# HC32F448 register map
File version: 1.0
CPU: CM4 r0p1, little endian, MPU, FPU, 4 interrupt priority bits
Registers are 32-bit, read-write, reset 0x0 unless marked. A register's access mark holds for its fields unless they carry their own. Offsets are from the block's base; [hi:lo] are bit positions; {n}, {i} and the like mark numbered series.

## PERIC
Base 0x40055400
0x0C SMC_ENAR
  [1] SMCEN
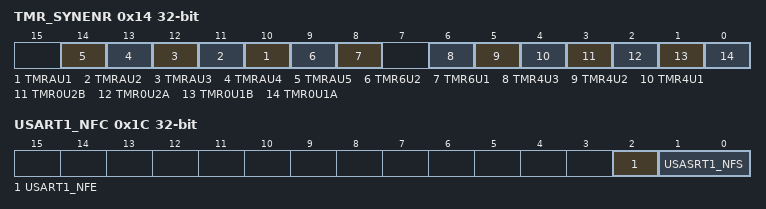
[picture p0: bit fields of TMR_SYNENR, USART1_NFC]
0x14 TMR_SYNENR
  [n+9] TMRAU{n} (n=1..5), [9] TMR6U2, [8] TMR6U1, [6] TMR4U3, [5] TMR4U2, [4] TMR4U1, [3] TMR0U2B, [2] TMR0U2A, [1] TMR0U1B, [0] TMR0U1A
0x1C USART1_NFC
  [2] USART1_NFE, [1:0] USASRT1_NFS

## PWC
Base 0x40048000; alternate view of CMU
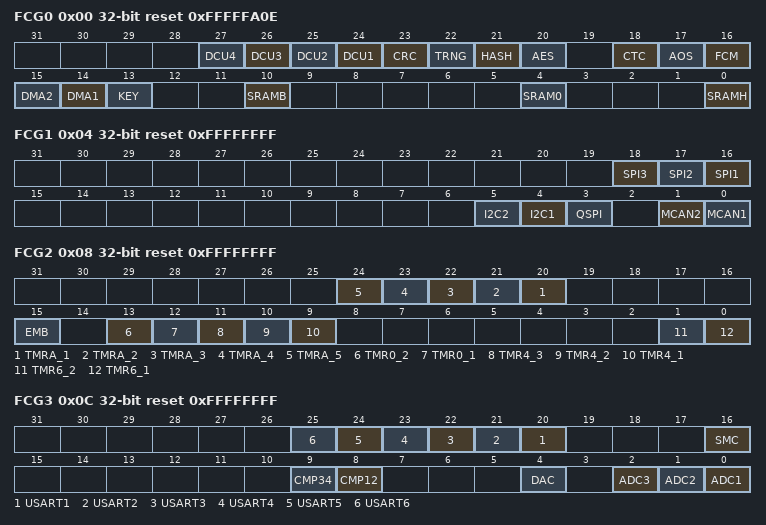
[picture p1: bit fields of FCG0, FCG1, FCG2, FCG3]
0x00 FCG0 reset 0xFFFFFA0E
  [n+23] DCU{n} (n=1..4), [23] CRC, [22] TRNG, [21] HASH, [20] AES, [18] CTC, [17] AOS, [16] FCM, [15] DMA2, [14] DMA1, [13] KEY, [10] SRAMB, [4] SRAM0, [0] SRAMH
0x04 FCG1 reset 0xFFFFFFFF
  [18] SPI3, [17] SPI2, [16] SPI1, [5] I2C2, [4] I2C1, [3] QSPI, [1] MCAN2, [0] MCAN1
0x08 FCG2 reset 0xFFFFFFFF
  [n+19] TMRA_{n} (n=1..5), [15] EMB, [13] TMR0_2, [12] TMR0_1, [11] TMR4_3, [10] TMR4_2, [9] TMR4_1, [1] TMR6_2, [0] TMR6_1
0x0C FCG3 reset 0xFFFFFFFF
  [n+19] USART{n} (n=1..6), [16] SMC, [9] CMP34, [8] CMP12, [4] DAC, [2] ADC3, [1] ADC2, [0] ADC1
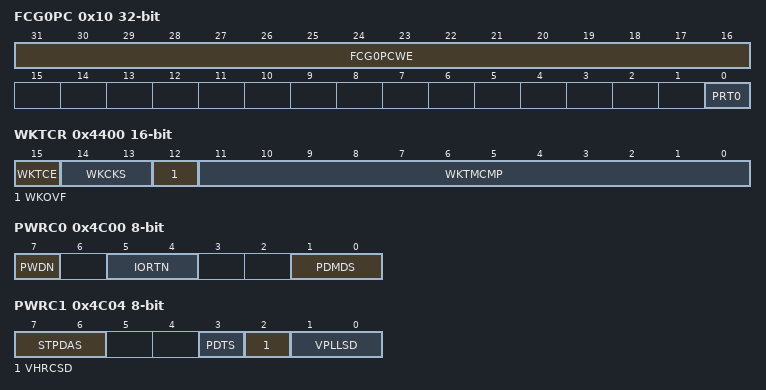
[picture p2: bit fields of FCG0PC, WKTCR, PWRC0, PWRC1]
0x10 FCG0PC
  [31:16] FCG0PCWE wo, [0] PRT0
0x4400 WKTCR 16-bit
  [15] WKTCE, [14:13] WKCKS, [12] WKOVF, [11:0] WKTMCMP
0x4C00 PWRC0 8-bit
  [7] PWDN, [5:4] IORTN, [1:0] PDMDS
0x4C04 PWRC1 8-bit
  [7:6] STPDAS, [3] PDTS, [2] VHRCSD, [1:0] VPLLSD
0x4C08 PWRC2 8-bit reset 0xF0
  [5:4] DVS
0x4C0C PWRC3 8-bit reset 0xF
  [3:0] DDAS
0x4C10 PWRC4 8-bit
  [7] ADBUFE
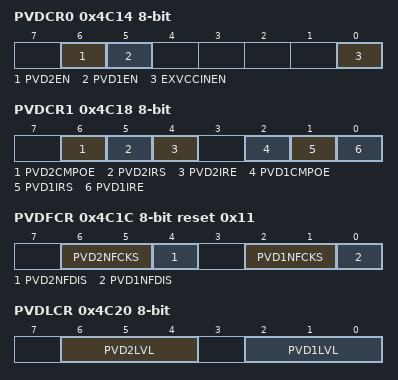
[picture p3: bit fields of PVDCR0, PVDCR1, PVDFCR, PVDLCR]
0x4C14 PVDCR0 8-bit
  [6] PVD2EN, [5] PVD1EN, [0] EXVCCINEN
0x4C18 PVDCR1 8-bit
  [6] PVD2CMPOE, [5] PVD2IRS, [4] PVD2IRE, [2] PVD1CMPOE, [1] PVD1IRS, [0] PVD1IRE
0x4C1C PVDFCR 8-bit reset 0x11
  [6:5] PVD2NFCKS, [4] PVD2NFDIS, [2:1] PVD1NFCKS, [0] PVD1NFDIS
0x4C20 PVDLCR 8-bit
  [6:4] PVD2LVL, [2:0] PVD1LVL
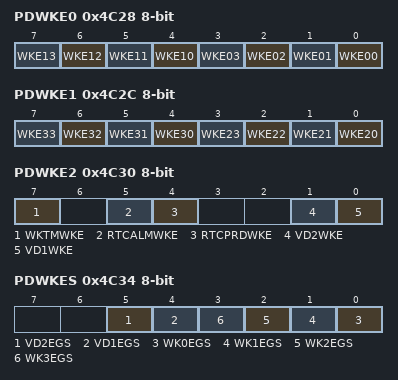
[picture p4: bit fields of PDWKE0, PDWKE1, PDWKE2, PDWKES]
0x4C28 PDWKE0 8-bit
  [n-6] WKE{n} (n=10..13), [n] WKE{n:02} (n=0..3)
0x4C2C PDWKE1 8-bit
  [n-26] WKE{n} (n=30..33), [n-20] WKE{n} (n=20..23)
0x4C30 PDWKE2 8-bit
  [7] WKTMWKE, [5] RTCALMWKE, [4] RTCPRDWKE, [1] VD2WKE, [0] VD1WKE
0x4C34 PDWKES 8-bit
  [5] VD2EGS, [4] VD1EGS, [n] WK{n}EGS (n=0..3)
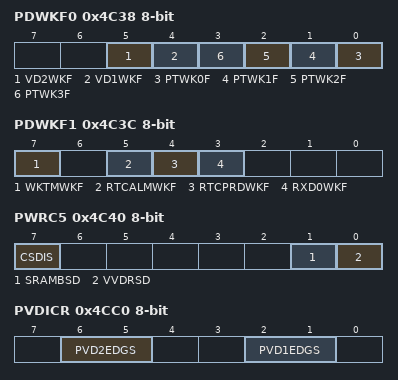
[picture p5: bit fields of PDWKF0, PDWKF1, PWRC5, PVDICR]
0x4C38 PDWKF0 8-bit
  [5] VD2WKF, [4] VD1WKF, [n] PTWK{n}F (n=0..3)
0x4C3C PDWKF1 8-bit
  [7] WKTMWKF, [5] RTCALMWKF, [4] RTCPRDWKF, [3] RXD0WKF
0x4C40 PWRC5 8-bit
  [7] CSDIS, [1] SRAMBSD, [0] VVDRSD
0x4C44 PWRC6 8-bit
  [1:0] RTCCKSEL
0x4CC0 PVDICR 8-bit
  [6:5] PVD2EDGS, [2:1] PVD1EDGS
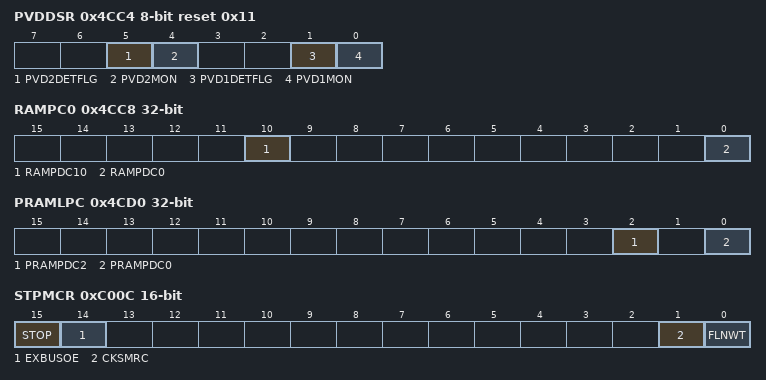
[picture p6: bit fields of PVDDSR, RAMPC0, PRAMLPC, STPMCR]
0x4CC4 PVDDSR 8-bit reset 0x11
  [5] PVD2DETFLG, [4] PVD2MON, [1] PVD1DETFLG, [0] PVD1MON
0x4CC8 RAMPC0
  [10] RAMPDC10, [0] RAMPDC0
0x4CCC RAMOPM reset 0x8043
  [15:0] RAMOPM
0x4CD0 PRAMLPC
  [2] PRAMPDC2, [0] PRAMPDC0
0xC00C STPMCR 16-bit
  [15] STOP, [14] EXBUSOE, [1] CKSMRC, [0] FLNWT
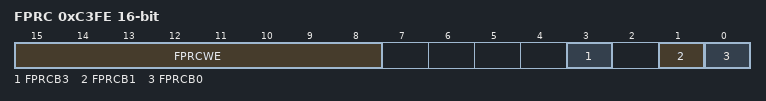
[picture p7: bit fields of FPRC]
0xC3FE FPRC 16-bit
  [15:8] FPRCWE, [3] FPRCB3, [1] FPRCB1, [0] FPRCB0

## QSPI
Base 0x9C000000
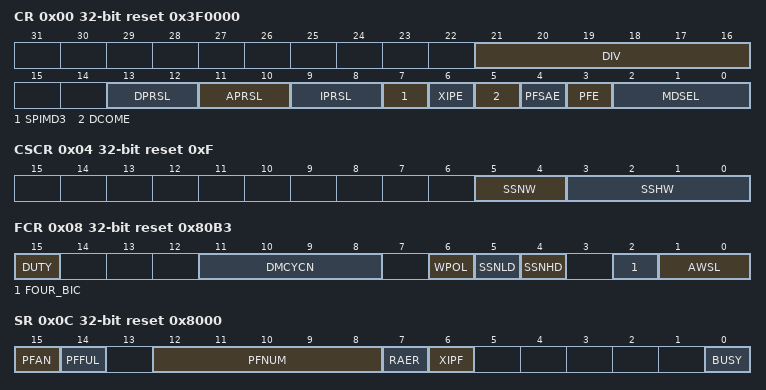
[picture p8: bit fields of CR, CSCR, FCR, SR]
0x00 CR reset 0x3F0000
  [21:16] DIV, [13:12] DPRSL, [11:10] APRSL, [9:8] IPRSL, [7] SPIMD3, [6] XIPE, [5] DCOME, [4] PFSAE, [3] PFE, [2:0] MDSEL
0x04 CSCR reset 0xF
  [5:4] SSNW, [3:0] SSHW
0x08 FCR reset 0x80B3
  [15] DUTY, [11:8] DMCYCN, [6] WPOL, [5] SSNLD, [4] SSNHD, [2] FOUR_BIC, [1:0] AWSL
0x0C SR ro reset 0x8000
  [15] PFAN, [14] PFFUL, [12:8] PFNUM, [7] RAER, [6] XIPF, [0] BUSY
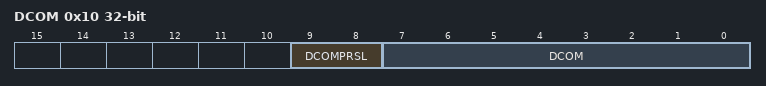
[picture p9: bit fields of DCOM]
0x10 DCOM
  [9:8] DCOMPRSL, [7:0] DCOM
0x14 CCMD
  [7:0] RIC
0x18 XCMD reset 0xFF
  [7:0] XIPMC
0x24 CLR wo
  [7] RAERCLR
0x804 EXAR
  [31:26] EXADR

## RMU
Base 0x4004CCE0
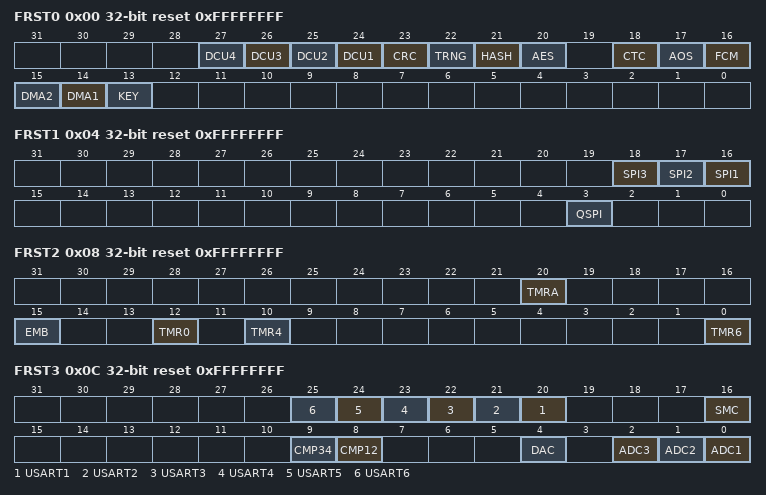
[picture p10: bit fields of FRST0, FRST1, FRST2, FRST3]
0x00 FRST0 reset 0xFFFFFFFF
  [n+23] DCU{n} (n=1..4), [23] CRC, [22] TRNG, [21] HASH, [20] AES, [18] CTC, [17] AOS, [16] FCM, [15] DMA2, [14] DMA1, [13] KEY
0x04 FRST1 reset 0xFFFFFFFF
  [18] SPI3, [17] SPI2, [16] SPI1, [3] QSPI
0x08 FRST2 reset 0xFFFFFFFF
  [20] TMRA, [15] EMB, [12] TMR0, [10] TMR4, [0] TMR6
0x0C FRST3 reset 0xFFFFFFFF
  [n+19] USART{n} (n=1..6), [16] SMC, [9] CMP34, [8] CMP12, [4] DAC, [2] ADC3, [1] ADC2, [0] ADC1
0x10 PRSTCR0 8-bit reset 0x40
  [5] LKUPREN
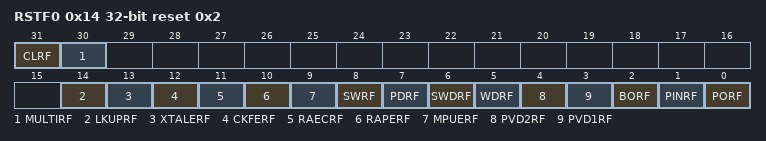
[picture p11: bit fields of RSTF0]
0x14 RSTF0 reset 0x2
  [31] CLRF, [30] MULTIRF, [14] LKUPRF, [13] XTALERF, [12] CKFERF, [11] RAECRF, [10] RAPERF, [9] MPUERF, [8] SWRF, [7] PDRF, [6] SWDRF, [5] WDRF, [4] PVD2RF, [3] PVD1RF, [2] BORF, [1] PINRF, [0] PORF
